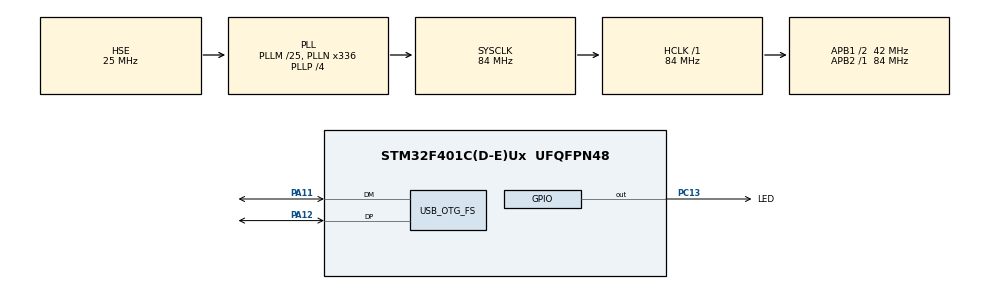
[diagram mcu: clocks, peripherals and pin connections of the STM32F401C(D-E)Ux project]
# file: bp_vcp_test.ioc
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Mcu.Family=STM32F4
Mcu.Name=STM32F401C(D-E)Ux
Mcu.Package=UFQFPN48
NVIC.OTG_FS_IRQn=true\:0\:0\:false\:false\:true\:false\:true\:true
NVIC.PriorityGroup=NVIC_PRIORITYGROUP_4
NVIC.TIM1_TRG_COM_TIM11_IRQn=true\:0\:0\:false\:false\:true\:true\:true\:true
PA11.Mode=Device_Only
PA11.Signal=USB_OTG_FS_DM
PA12.Mode=Device_Only
PA12.Signal=USB_OTG_FS_DP
PA13.Mode=Serial_Wire
PA13.Signal=SYS_JTMS-SWDIO
PA14.Mode=Serial_Wire
PA14.Signal=SYS_JTCK-SWCLK
PC13-ANTI_TAMP.GPIO_Label=LED
PC13-ANTI_TAMP.GPIO_ModeDefaultOutputPP=GPIO_MODE_OUTPUT_OD
PC13-ANTI_TAMP.GPIO_PuPd=GPIO_PULLUP
PC13-ANTI_TAMP.PinState=GPIO_PIN_SET
PC13-ANTI_TAMP.Signal=GPIO_Output
PH0\ -\ OSC_IN.Mode=HSE-External-Oscillator
PH0\ -\ OSC_IN.Signal=RCC_OSC_IN
PH1\ -\ OSC_OUT.Mode=HSE-External-Oscillator
PH1\ -\ OSC_OUT.Signal=RCC_OSC_OUT
ProjectManager.HeapSize=0x600
ProjectManager.StackSize=0x400
ProjectManager.TargetToolchain=STM32CubeIDE
RCC.48MHZClocksFreq_Value=48000000
RCC.AHBFreq_Value=84000000
RCC.APB1CLKDivider=RCC_HCLK_DIV2
RCC.APB1Freq_Value=42000000
RCC.APB1TimFreq_Value=84000000
RCC.APB2Freq_Value=84000000
RCC.APB2TimFreq_Value=84000000
RCC.CortexFreq_Value=84000000
RCC.HCLKFreq_Value=84000000
RCC.HSE_VALUE=25000000
RCC.HSI_VALUE=16000000
RCC.LSE_VALUE=32768
RCC.PLLM=25
RCC.PLLN=336
RCC.PLLP=RCC_PLLP_DIV4
RCC.PLLQ=7
RCC.SYSCLKFreq_VALUE=84000000
RCC.SYSCLKSource=RCC_SYSCLKSOURCE_PLLCLK
RCC.VCOOutputFreq_Value=336000000
TIM11.Channel=TIM_CHANNEL_1
TIM11.Period=8400
TIM11.Prescaler=10000
USB_DEVICE.CLASS_NAME_FS=CDC
USB_DEVICE.VirtualMode-CDC_FS=Cdc
USB_DEVICE.VirtualModeFS=Cdc_FS
USB_OTG_FS.VirtualMode=Device_Only
VP_TIM11_VS_ClockSourceINT.Mode=Enable_Timer
VP_TIM11_VS_no_output1.Mode=Output Compare1 No Output
VP_USB_DEVICE_VS_USB_DEVICE_CDC_FS.Mode=CDC_FS
board=custom

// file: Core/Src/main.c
/* USER CODE BEGIN Header */
/**
  ******************************************************************************
  * @file           : main.c
  * @brief          : Main program body
  ******************************************************************************
  * @attention
  *
  * Copyright (c) 2023 STMicroelectronics.
  * All rights reserved.
  *
  * This software is licensed under terms that can be found in the LICENSE file
  * in the root directory of this software component.
  * If no LICENSE file comes with this software, it is provided AS-IS.
  *
  ******************************************************************************
  */
/* USER CODE END Header */
#include "main.h"
#include "usb_device.h"

/* USER CODE BEGIN Includes */

//***
#include "usbd_cdc_if.h"
#include <string.h>
//***

/* USER CODE END Includes */

TIM_HandleTypeDef htim11;

/* USER CODE BEGIN PV */

//***
volatile uint8_t transmit_en = 0;
//***

/* USER CODE END PV */

void SystemClock_Config(void);
static void MX_GPIO_Init(void);
static void MX_TIM11_Init(void);

/* USER CODE BEGIN 0 */

//***
/*
 * Cálculo de ARR para um período de tempo T:
 *
 * ARR = (T*FCLK)/PSC
 *
 * T em segundos
 * FCLK: Frequência do clock em Hz (84 MHz para o F401)
 * PSC: Prescaler (0 a 65535)
 *
 * Exemplo para um período de 0.5 segundos:
 * ARR = (0.5*84E6)/10000 = 4200
 *
 * Obs.: CDC_Transmit_FS() não pode ser chamada dentro da função de tratamento de interrupção do temporizador
 */
void HAL_TIM_PeriodElapsedCallback(TIM_HandleTypeDef *htim) {
	transmit_en = 1;
}
//***

/* USER CODE END 0 */

int main(void)
{

  /* MCU Configuration--------------------------------------------------------*/

  /* Reset of all peripherals, Initializes the Flash interface and the Systick. */
  HAL_Init();

  /* Configure the system clock */
  SystemClock_Config();

  /* Initialize all configured peripherals */
  MX_GPIO_Init();
  MX_USB_DEVICE_Init();
  MX_TIM11_Init();
  /* USER CODE BEGIN 2 */

  //***
  HAL_TIM_Base_Start_IT(&htim11);
  //***

  /* USER CODE END 2 */

  /* Infinite loop */
  /* USER CODE BEGIN WHILE */
  while (1)
  {

	  //***
	  if(transmit_en) {
		  uint8_t msg_buffer[] = "Hello\n";
		  CDC_Transmit_FS(msg_buffer, strlen((const char *)msg_buffer));
		  transmit_en = 0;
	  }
	  //***

	  /* USER CODE END WHILE */

  }
}

void SystemClock_Config(void)
{
  RCC_OscInitTypeDef RCC_OscInitStruct = {0};
  RCC_ClkInitTypeDef RCC_ClkInitStruct = {0};

  /** Configure the main internal regulator output voltage
  */
  __HAL_RCC_PWR_CLK_ENABLE();
  __HAL_PWR_VOLTAGESCALING_CONFIG(PWR_REGULATOR_VOLTAGE_SCALE2);

  /** Initializes the RCC Oscillators according to the specified parameters
  * in the RCC_OscInitTypeDef structure.
  */
  RCC_OscInitStruct.OscillatorType = RCC_OSCILLATORTYPE_HSE;
  RCC_OscInitStruct.HSEState = RCC_HSE_ON;
  RCC_OscInitStruct.PLL.PLLState = RCC_PLL_ON;
  RCC_OscInitStruct.PLL.PLLSource = RCC_PLLSOURCE_HSE;
  RCC_OscInitStruct.PLL.PLLM = 25;
  RCC_OscInitStruct.PLL.PLLN = 336;
  RCC_OscInitStruct.PLL.PLLP = RCC_PLLP_DIV4;
  RCC_OscInitStruct.PLL.PLLQ = 7;
  if (HAL_RCC_OscConfig(&RCC_OscInitStruct) != HAL_OK)
  {
    Error_Handler();
  }

  /** Initializes the CPU, AHB and APB buses clocks
  */
  RCC_ClkInitStruct.ClockType = RCC_CLOCKTYPE_HCLK|RCC_CLOCKTYPE_SYSCLK
                              |RCC_CLOCKTYPE_PCLK1|RCC_CLOCKTYPE_PCLK2;
  RCC_ClkInitStruct.SYSCLKSource = RCC_SYSCLKSOURCE_PLLCLK;
  RCC_ClkInitStruct.AHBCLKDivider = RCC_SYSCLK_DIV1;
  RCC_ClkInitStruct.APB1CLKDivider = RCC_HCLK_DIV2;
  RCC_ClkInitStruct.APB2CLKDivider = RCC_HCLK_DIV1;

  if (HAL_RCC_ClockConfig(&RCC_ClkInitStruct, FLASH_LATENCY_2) != HAL_OK)
  {
    Error_Handler();
  }
}

static void MX_TIM11_Init(void)
{

  TIM_OC_InitTypeDef sConfigOC = {0};

  htim11.Instance = TIM11;
  htim11.Init.Prescaler = 10000;
  htim11.Init.CounterMode = TIM_COUNTERMODE_UP;
  htim11.Init.Period = 8400;
  htim11.Init.ClockDivision = TIM_CLOCKDIVISION_DIV1;
  htim11.Init.AutoReloadPreload = TIM_AUTORELOAD_PRELOAD_DISABLE;
  if (HAL_TIM_Base_Init(&htim11) != HAL_OK)
  {
    Error_Handler();
  }
  if (HAL_TIM_OC_Init(&htim11) != HAL_OK)
  {
    Error_Handler();
  }
  sConfigOC.OCMode = TIM_OCMODE_TIMING;
  sConfigOC.Pulse = 0;
  sConfigOC.OCPolarity = TIM_OCPOLARITY_HIGH;
  sConfigOC.OCFastMode = TIM_OCFAST_DISABLE;
  if (HAL_TIM_OC_ConfigChannel(&htim11, &sConfigOC, TIM_CHANNEL_1) != HAL_OK)
  {
    Error_Handler();
  }

}

static void MX_GPIO_Init(void)
{
  GPIO_InitTypeDef GPIO_InitStruct = {0};

  /* GPIO Ports Clock Enable */
  __HAL_RCC_GPIOC_CLK_ENABLE();
  __HAL_RCC_GPIOH_CLK_ENABLE();
  __HAL_RCC_GPIOA_CLK_ENABLE();

  /*Configure GPIO pin Output Level */
  HAL_GPIO_WritePin(LED_GPIO_Port, LED_Pin, GPIO_PIN_SET);

  /*Configure GPIO pin : LED_Pin */
  GPIO_InitStruct.Pin = LED_Pin;
  GPIO_InitStruct.Mode = GPIO_MODE_OUTPUT_OD;
  GPIO_InitStruct.Pull = GPIO_PULLUP;
  GPIO_InitStruct.Speed = GPIO_SPEED_FREQ_LOW;
  HAL_GPIO_Init(LED_GPIO_Port, &GPIO_InitStruct);

}

void Error_Handler(void)
{
  __disable_irq();
  while (1)
  {
  }
}
